AUTOSAR XML (schema 4-2-2)
package /STELLANTIS/EPT/SASWCs
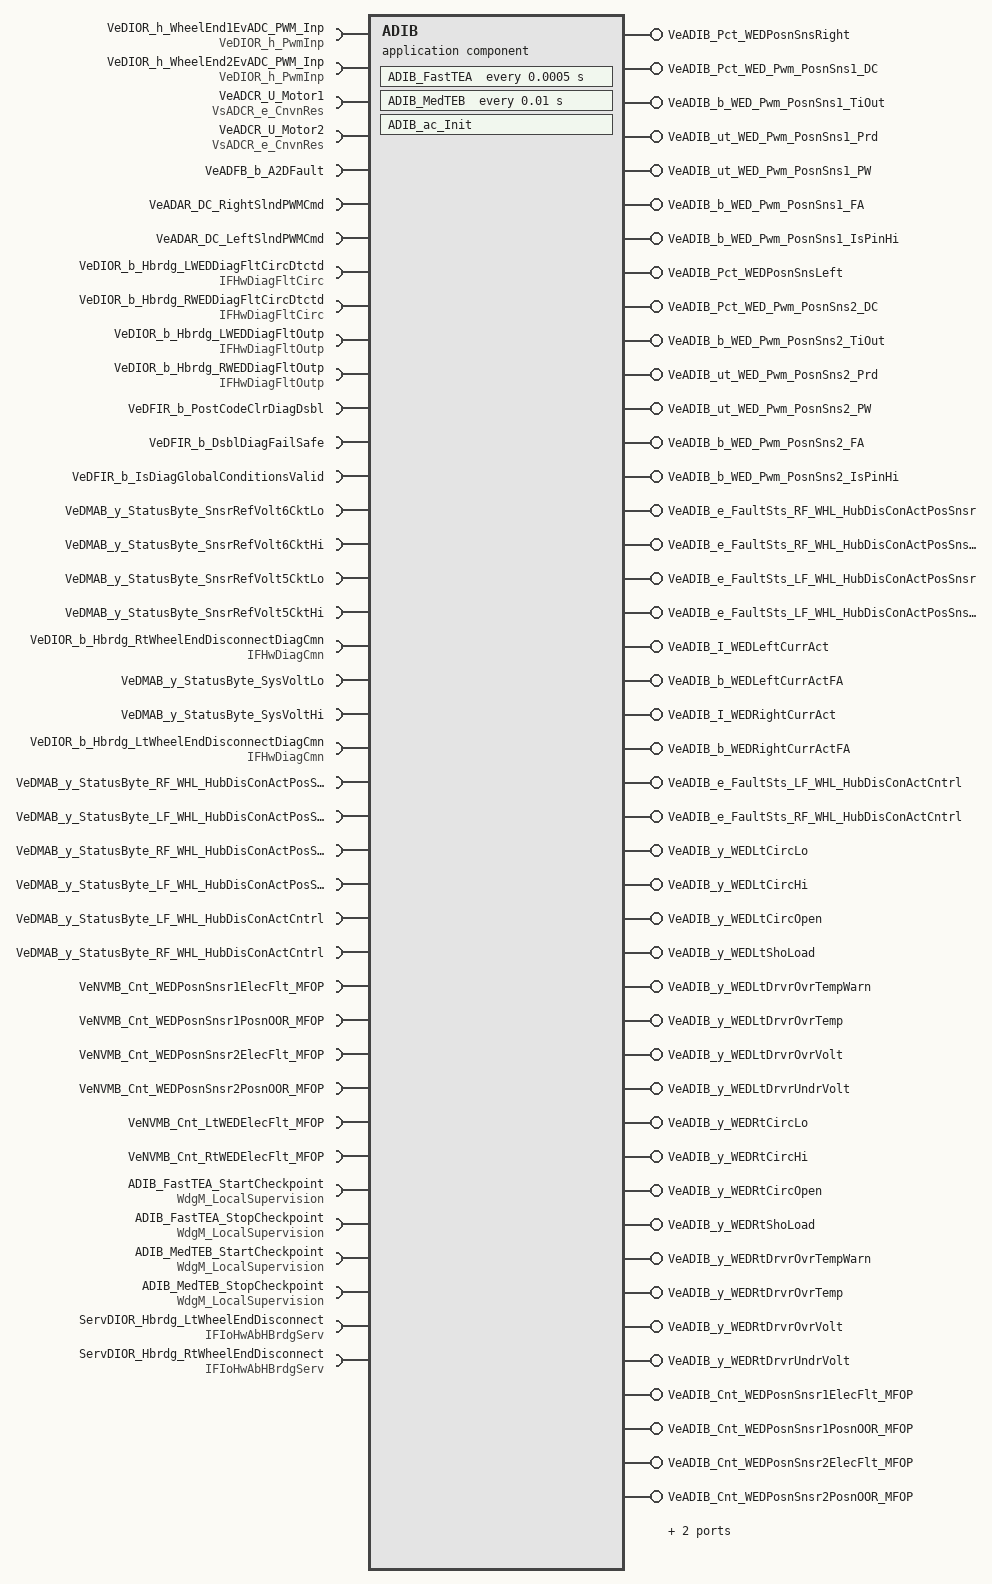
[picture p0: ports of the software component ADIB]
  application sw component type ADIB
    34 x require port:
      VeDIOR_h_WheelEnd1EvADC_PWM_Inp: variation-point={short-label=vpVeDIOR_h_WheelEnd1EvADC_PWM_Inp, sw-syscond=1}, required-interface=VeDIOR_h_PwmInp
        required-com-specs:
          data-element=VeDIOR_Pct_PwmInp_DC, init-value=0
          data-element=VeDIOR_t_PwmInp_PW, init-value=0
          data-element=VeDIOR_t_PwmInp_Prd, init-value=0
          data-element=VeDIOR_b_IsPinHi, init-value=0
          data-element=VeDIOR_b_PwmInp_TiOutSts, init-value=0
          data-element=VeDIOR_b_PwmInp_EnbldSts, init-value=0
      VeDIOR_h_WheelEnd2EvADC_PWM_Inp: variation-point={short-label=vpVeDIOR_h_WheelEnd2EvADC_PWM_Inp, sw-syscond=1}, required-interface=VeDIOR_h_PwmInp
        required-com-specs:
          data-element=VeDIOR_Pct_PwmInp_DC, init-value=0
          data-element=VeDIOR_t_PwmInp_PW, init-value=0
          data-element=VeDIOR_t_PwmInp_Prd, init-value=0
          data-element=VeDIOR_b_IsPinHi, init-value=0
          data-element=VeDIOR_b_PwmInp_TiOutSts, init-value=0
          data-element=VeDIOR_b_PwmInp_EnbldSts, init-value=0
      VeADCR_U_Motor1: variation-point={short-label=vpVeADCR_U_Motor1, sw-syscond=1}, nonqueued-receiver-com-spec{data-element=VsADCR_e_CnvnRes, init-value={short-label=DefaultInitValue_IDTRAdcInpResData, fields=[0, 0]}}, required-interface=VsADCR_e_CnvnRes
      VeADCR_U_Motor2: variation-point={short-label=vpVeADCR_U_Motor2, sw-syscond=1}, nonqueued-receiver-com-spec{data-element=VsADCR_e_CnvnRes, init-value={short-label=DefaultInitValue_IDTRAdcInpResData, fields=[0, 0]}}, required-interface=VsADCR_e_CnvnRes
      VeADFB_b_A2DFault: variation-point={short-label=vpVeADFB_b_A2DFault, sw-syscond=1}, nonqueued-receiver-com-spec{data-element=Value, init-value=0}, required-interface=VeADFB_b_A2DFault
      VeADAR_DC_RightSlndPWMCmd: variation-point={short-label=vpVeADAR_DC_RightSlndPWMCmd, sw-syscond=1}, nonqueued-receiver-com-spec{data-element=Value, init-value=0}, required-interface=VeADAR_DC_RightSlndPWMCmd
      VeADAR_DC_LeftSlndPWMCmd: variation-point={short-label=vpVeADAR_DC_LeftSlndPWMCmd, sw-syscond=1}, nonqueued-receiver-com-spec{data-element=Value, init-value=0}, required-interface=VeADAR_DC_LeftSlndPWMCmd
      VeDIOR_b_Hbrdg_LWEDDiagFltCircDtctd: variation-point={short-label=vpVeDIOR_b_Hbrdg_LWEDDiagFltCircDtctd, sw-syscond=1}, required-interface=IFHwDiagFltCirc
        required-com-specs:
          {data-element=CircShoLo, init-value={short-label=DefaultInitValue_IDTCondPresence, fields=[0, 0, 0, 0, 0, 0, 0, 0]}}
          {data-element=CircShoHi, init-value={short-label=DefaultInitValue_IDTCondPresence, fields=[0, 0, 0, 0, 0, 0, 0, 0]}}
          {data-element=CircOpen, init-value={short-label=DefaultInitValue_IDTCondPresence, fields=[0, 0, 0, 0, 0, 0, 0, 0]}}
          {data-element=ShoLoad, init-value={short-label=DefaultInitValue_IDTCondPresence, fields=[0, 0, 0, 0, 0, 0, 0, 0]}}
      VeDIOR_b_Hbrdg_RWEDDiagFltCircDtctd: variation-point={short-label=vpVeDIOR_b_Hbrdg_RWEDDiagFltCircDtctd, sw-syscond=1}, required-interface=IFHwDiagFltCirc
        required-com-specs:
          {data-element=CircShoLo, init-value={short-label=DefaultInitValue_IDTCondPresence, fields=[0, 0, 0, 0, 0, 0, 0, 0]}}
          {data-element=CircShoHi, init-value={short-label=DefaultInitValue_IDTCondPresence, fields=[0, 0, 0, 0, 0, 0, 0, 0]}}
          {data-element=CircOpen, init-value={short-label=DefaultInitValue_IDTCondPresence, fields=[0, 0, 0, 0, 0, 0, 0, 0]}}
          {data-element=ShoLoad, init-value={short-label=DefaultInitValue_IDTCondPresence, fields=[0, 0, 0, 0, 0, 0, 0, 0]}}
      VeDIOR_b_Hbrdg_LWEDDiagFltOutp: variation-point={short-label=vpVeDIOR_b_Hbrdg_LWEDDiagFltOutp, sw-syscond=1}, required-interface=IFHwDiagFltOutp
        required-com-specs:
          {data-element=DrvrOvrTempWarn, init-value={short-label=DefaultInitValue_IDTCondPresence, fields=[0, 0, 0, 0, 0, 0, 0, 0]}}
          {data-element=DrvrOvrTempDtctd, init-value={short-label=DefaultInitValue_IDTCondPresence, fields=[0, 0, 0, 0, 0, 0, 0, 0]}}
          {data-element=DrvrOvrVoltDtctd, init-value={short-label=DefaultInitValue_IDTCondPresence, fields=[0, 0, 0, 0, 0, 0, 0, 0]}}
          {data-element=DrvrUndrVoltDtctd, init-value={short-label=DefaultInitValue_IDTCondPresence, fields=[0, 0, 0, 0, 0, 0, 0, 0]}}
      VeDIOR_b_Hbrdg_RWEDDiagFltOutp: variation-point={short-label=vpVeDIOR_b_Hbrdg_RWEDDiagFltOutp, sw-syscond=1}, required-interface=IFHwDiagFltOutp
        required-com-specs:
          {data-element=DrvrOvrTempWarn, init-value={short-label=DefaultInitValue_IDTCondPresence, fields=[0, 0, 0, 0, 0, 0, 0, 0]}}
          {data-element=DrvrOvrTempDtctd, init-value={short-label=DefaultInitValue_IDTCondPresence, fields=[0, 0, 0, 0, 0, 0, 0, 0]}}
          {data-element=DrvrOvrVoltDtctd, init-value={short-label=DefaultInitValue_IDTCondPresence, fields=[0, 0, 0, 0, 0, 0, 0, 0]}}
          {data-element=DrvrUndrVoltDtctd, init-value={short-label=DefaultInitValue_IDTCondPresence, fields=[0, 0, 0, 0, 0, 0, 0, 0]}}
      VeDFIR_b_PostCodeClrDiagDsbl: variation-point={short-label=vpVeDFIR_b_PostCodeClrDiagDsbl, sw-syscond=1}, nonqueued-receiver-com-spec{data-element=Value, init-value=0}, required-interface=VeDFIR_b_PostCodeClrDiagDsbl
      VeDFIR_b_DsblDiagFailSafe: variation-point={short-label=vpVeDFIR_b_DsblDiagFailSafe, sw-syscond=1}, nonqueued-receiver-com-spec{data-element=Value, init-value=0}, required-interface=VeDFIR_b_DsblDiagFailSafe
      VeDFIR_b_IsDiagGlobalConditionsValid: variation-point={short-label=vpVeDFIR_b_IsDiagGlobalConditionsValid, sw-syscond=1}, nonqueued-receiver-com-spec{data-element=Value, init-value=0}, required-interface=VeDFIR_b_IsDiagGlobalConditionsValid
      VeDMAB_y_StatusByte_SnsrRefVolt6CktLo: variation-point={short-label=vpVeDMAB_y_StatusByte_SnsrRefVolt6CktLo, sw-syscond=1}, nonqueued-receiver-com-spec{data-element=Value, init-value=0}, required-interface=VeDMAB_y_StatusByte_SnsrRefVolt6CktLo
      VeDMAB_y_StatusByte_SnsrRefVolt6CktHi: variation-point={short-label=vpVeDMAB_y_StatusByte_SnsrRefVolt6CktHi, sw-syscond=1}, nonqueued-receiver-com-spec{data-element=Value, init-value=0}, required-interface=VeDMAB_y_StatusByte_SnsrRefVolt6CktHi
      VeDMAB_y_StatusByte_SnsrRefVolt5CktLo: variation-point={short-label=vpVeDMAB_y_StatusByte_SnsrRefVolt5CktLo, sw-syscond=1}, nonqueued-receiver-com-spec{data-element=Value, init-value=0}, required-interface=VeDMAB_y_StatusByte_SnsrRefVolt5CktLo
      VeDMAB_y_StatusByte_SnsrRefVolt5CktHi: variation-point={short-label=vpVeDMAB_y_StatusByte_SnsrRefVolt5CktHi, sw-syscond=1}, nonqueued-receiver-com-spec{data-element=Value, init-value=0}, required-interface=VeDMAB_y_StatusByte_SnsrRefVolt5CktHi
      VeDIOR_b_Hbrdg_RtWheelEndDisconnectDiagCmn: variation-point={short-label=vpVeDIOR_b_Hbrdg_RtWheelEndDisconnectDiagCmn, sw-syscond=1}, nonqueued-receiver-com-spec{data-element=b_FailrPrsnt, init-value=0}, required-interface=IFHwDiagCmn
      VeDMAB_y_StatusByte_SysVoltLo: variation-point={short-label=vpVeDMAB_y_StatusByte_SysVoltLo, sw-syscond=1}, nonqueued-receiver-com-spec{data-element=Value, init-value=0}, required-interface=VeDMAB_y_StatusByte_SysVoltLo
      VeDMAB_y_StatusByte_SysVoltHi: variation-point={short-label=vpVeDMAB_y_StatusByte_SysVoltHi, sw-syscond=1}, nonqueued-receiver-com-spec{data-element=Value, init-value=0}, required-interface=VeDMAB_y_StatusByte_SysVoltHi
      VeDIOR_b_Hbrdg_LtWheelEndDisconnectDiagCmn: variation-point={short-label=vpVeDIOR_b_Hbrdg_LtWheelEndDisconnectDiagCmn, sw-syscond=1}, nonqueued-receiver-com-spec{data-element=b_FailrPrsnt, init-value=0}, required-interface=IFHwDiagCmn
      VeDMAB_y_StatusByte_RF_WHL_HubDisConActPosSnsr: variation-point={short-label=vpVeDMAB_y_StatusByte_RF_WHL_HubDisConActPosSnsr, sw-syscond=1}, nonqueued-receiver-com-spec{data-element=Value, init-value=0}, required-interface=VeDMAB_y_StatusByte_RF_WHL_HubDisConActPosSnsr
      VeDMAB_y_StatusByte_LF_WHL_HubDisConActPosSnsrCktPerf: variation-point={short-label=vpVeDMAB_y_StatusByte_LF_WHL_HubDisConActPosSnsrCktPerf, sw-syscond=1}, nonqueued-receiver-com-spec{data-element=Value, init-value=0}, required-interface=VeDMAB_y_StatusByte_LF_WHL_HubDisConActPosSnsrCktPerf
      VeDMAB_y_StatusByte_RF_WHL_HubDisConActPosSnsrCktPerf: variation-point={short-label=vpVeDMAB_y_StatusByte_RF_WHL_HubDisConActPosSnsrCktPerf, sw-syscond=1}, nonqueued-receiver-com-spec{data-element=Value, init-value=0}, required-interface=VeDMAB_y_StatusByte_RF_WHL_HubDisConActPosSnsrCktPerf
      VeDMAB_y_StatusByte_LF_WHL_HubDisConActPosSnsr: variation-point={short-label=vpVeDMAB_y_StatusByte_LF_WHL_HubDisConActPosSnsr, sw-syscond=1}, nonqueued-receiver-com-spec{data-element=Value, init-value=0}, required-interface=VeDMAB_y_StatusByte_LF_WHL_HubDisConActPosSnsr
      VeDMAB_y_StatusByte_LF_WHL_HubDisConActCntrl: variation-point={short-label=vpVeDMAB_y_StatusByte_LF_WHL_HubDisConActCntrl, sw-syscond=1}, nonqueued-receiver-com-spec{data-element=Value, init-value=0}, required-interface=VeDMAB_y_StatusByte_LF_WHL_HubDisConActCntrl
      VeDMAB_y_StatusByte_RF_WHL_HubDisConActCntrl: variation-point={short-label=vpVeDMAB_y_StatusByte_RF_WHL_HubDisConActCntrl, sw-syscond=1}, nonqueued-receiver-com-spec{data-element=Value, init-value=0}, required-interface=VeDMAB_y_StatusByte_RF_WHL_HubDisConActCntrl
      VeNVMB_Cnt_WEDPosnSnsr1ElecFlt_MFOP: variation-point={short-label=vpVeNVMB_Cnt_WEDPosnSnsr1ElecFlt_MFOP, sw-syscond=1}, nonqueued-receiver-com-spec{data-element=Value, init-value=0}, required-interface=VeNVMB_Cnt_WEDPosnSnsr1ElecFlt_MFOP
      VeNVMB_Cnt_WEDPosnSnsr1PosnOOR_MFOP: variation-point={short-label=vpVeNVMB_Cnt_WEDPosnSnsr1PosnOOR_MFOP, sw-syscond=1}, nonqueued-receiver-com-spec{data-element=Value, init-value=0}, required-interface=VeNVMB_Cnt_WEDPosnSnsr1PosnOOR_MFOP
      VeNVMB_Cnt_WEDPosnSnsr2ElecFlt_MFOP: variation-point={short-label=vpVeNVMB_Cnt_WEDPosnSnsr2ElecFlt_MFOP, sw-syscond=1}, nonqueued-receiver-com-spec{data-element=Value, init-value=0}, required-interface=VeNVMB_Cnt_WEDPosnSnsr2ElecFlt_MFOP
      VeNVMB_Cnt_WEDPosnSnsr2PosnOOR_MFOP: variation-point={short-label=vpVeNVMB_Cnt_WEDPosnSnsr2PosnOOR_MFOP, sw-syscond=1}, nonqueued-receiver-com-spec{data-element=Value, init-value=0}, required-interface=VeNVMB_Cnt_WEDPosnSnsr2PosnOOR_MFOP
      VeNVMB_Cnt_LtWEDElecFlt_MFOP: variation-point={short-label=vpVeNVMB_Cnt_LtWEDElecFlt_MFOP, sw-syscond=1}, nonqueued-receiver-com-spec{data-element=Value, init-value=0}, required-interface=VeNVMB_Cnt_LtWEDElecFlt_MFOP
      VeNVMB_Cnt_RtWEDElecFlt_MFOP: variation-point={short-label=vpVeNVMB_Cnt_RtWEDElecFlt_MFOP, sw-syscond=1}, nonqueued-receiver-com-spec{data-element=Value, init-value=0}, required-interface=VeNVMB_Cnt_RtWEDElecFlt_MFOP
    46 x provide port:
      VeADIB_Pct_WEDPosnSnsRight: variation-point={short-label=vpVeADIB_Pct_WEDPosnSnsRight, sw-syscond=1}, nonqueued-sender-com-spec{data-element=Value, init-value=0}, provided-interface=VeADIB_Pct_WEDPosnSnsRight
      VeADIB_Pct_WED_Pwm_PosnSns1_DC: variation-point={short-label=vpVeADIB_Pct_WED_Pwm_PosnSns1_DC, sw-syscond=1}, nonqueued-sender-com-spec{data-element=Value, init-value=0}, provided-interface=VeADIB_Pct_WED_Pwm_PosnSns1_DC
      VeADIB_b_WED_Pwm_PosnSns1_TiOut: variation-point={short-label=vpVeADIB_b_WED_Pwm_PosnSns1_TiOut, sw-syscond=1}, nonqueued-sender-com-spec{data-element=Value, init-value=0}, provided-interface=VeADIB_b_WED_Pwm_PosnSns1_TiOut
      VeADIB_ut_WED_Pwm_PosnSns1_Prd: variation-point={short-label=vpVeADIB_ut_WED_Pwm_PosnSns1_Prd, sw-syscond=1}, nonqueued-sender-com-spec{data-element=Value, init-value=0}, provided-interface=VeADIB_ut_WED_Pwm_PosnSns1_Prd
      VeADIB_ut_WED_Pwm_PosnSns1_PW: variation-point={short-label=vpVeADIB_ut_WED_Pwm_PosnSns1_PW, sw-syscond=1}, nonqueued-sender-com-spec{data-element=Value, init-value=0}, provided-interface=VeADIB_ut_WED_Pwm_PosnSns1_PW
      VeADIB_b_WED_Pwm_PosnSns1_FA: variation-point={short-label=vpVeADIB_b_WED_Pwm_PosnSns1_FA, sw-syscond=1}, nonqueued-sender-com-spec{data-element=Value, init-value=0}, provided-interface=VeADIB_b_WED_Pwm_PosnSns1_FA
      VeADIB_b_WED_Pwm_PosnSns1_IsPinHi: variation-point={short-label=vpVeADIB_b_WED_Pwm_PosnSns1_IsPinHi, sw-syscond=1}, nonqueued-sender-com-spec{data-element=Value, init-value=0}, provided-interface=VeADIB_b_WED_Pwm_PosnSns1_IsPinHi
      VeADIB_Pct_WEDPosnSnsLeft: variation-point={short-label=vpVeADIB_Pct_WEDPosnSnsLeft, sw-syscond=1}, nonqueued-sender-com-spec{data-element=Value, init-value=0}, provided-interface=VeADIB_Pct_WEDPosnSnsLeft
      VeADIB_Pct_WED_Pwm_PosnSns2_DC: variation-point={short-label=vpVeADIB_Pct_WED_Pwm_PosnSns2_DC, sw-syscond=1}, nonqueued-sender-com-spec{data-element=Value, init-value=0}, provided-interface=VeADIB_Pct_WED_Pwm_PosnSns2_DC
      VeADIB_b_WED_Pwm_PosnSns2_TiOut: variation-point={short-label=vpVeADIB_b_WED_Pwm_PosnSns2_TiOut, sw-syscond=1}, nonqueued-sender-com-spec{data-element=Value, init-value=0}, provided-interface=VeADIB_b_WED_Pwm_PosnSns2_TiOut
      VeADIB_ut_WED_Pwm_PosnSns2_Prd: variation-point={short-label=vpVeADIB_ut_WED_Pwm_PosnSns2_Prd, sw-syscond=1}, nonqueued-sender-com-spec{data-element=Value, init-value=0}, provided-interface=VeADIB_ut_WED_Pwm_PosnSns2_Prd
      VeADIB_ut_WED_Pwm_PosnSns2_PW: variation-point={short-label=vpVeADIB_ut_WED_Pwm_PosnSns2_PW, sw-syscond=1}, nonqueued-sender-com-spec{data-element=Value, init-value=0}, provided-interface=VeADIB_ut_WED_Pwm_PosnSns2_PW
      VeADIB_b_WED_Pwm_PosnSns2_FA: variation-point={short-label=vpVeADIB_b_WED_Pwm_PosnSns2_FA, sw-syscond=1}, nonqueued-sender-com-spec{data-element=Value, init-value=0}, provided-interface=VeADIB_b_WED_Pwm_PosnSns2_FA
      VeADIB_b_WED_Pwm_PosnSns2_IsPinHi: variation-point={short-label=vpVeADIB_b_WED_Pwm_PosnSns2_IsPinHi, sw-syscond=1}, nonqueued-sender-com-spec{data-element=Value, init-value=0}, provided-interface=VeADIB_b_WED_Pwm_PosnSns2_IsPinHi
      VeADIB_e_FaultSts_RF_WHL_HubDisConActPosSnsr: variation-point={short-label=vpVeADIB_e_FaultSts_RF_WHL_HubDisConActPosSnsr, sw-syscond=1}, nonqueued-sender-com-spec{data-element=Value, init-value=CeDFIB_e_Init}, provided-interface=VeADIB_e_FaultSts_RF_WHL_HubDisConActPosSnsr
      VeADIB_e_FaultSts_RF_WHL_HubDisConActPosSnsrCktPerf: variation-point={short-label=vpVeADIB_e_FaultSts_RF_WHL_HubDisConActPosSnsrCktPerf, sw-syscond=1}, nonqueued-sender-com-spec{data-element=Value, init-value=CeDFIB_e_Init}, provided-interface=VeADIB_e_FaultSts_RF_WHL_HubDisConActPosSnsrCktPerf
      VeADIB_e_FaultSts_LF_WHL_HubDisConActPosSnsr: variation-point={short-label=vpVeADIB_e_FaultSts_LF_WHL_HubDisConActPosSnsr, sw-syscond=1}, nonqueued-sender-com-spec{data-element=Value, init-value=CeDFIB_e_Init}, provided-interface=VeADIB_e_FaultSts_LF_WHL_HubDisConActPosSnsr
      VeADIB_e_FaultSts_LF_WHL_HubDisConActPosSnsrCktPerf: variation-point={short-label=vpVeADIB_e_FaultSts_LF_WHL_HubDisConActPosSnsrCktPerf, sw-syscond=1}, nonqueued-sender-com-spec{data-element=Value, init-value=CeDFIB_e_Init}, provided-interface=VeADIB_e_FaultSts_LF_WHL_HubDisConActPosSnsrCktPerf
      VeADIB_I_WEDLeftCurrAct: variation-point={short-label=vpVeADIB_I_WEDLeftCurrAct, sw-syscond=1}, nonqueued-sender-com-spec{data-element=Value, init-value=0}, provided-interface=VeADIB_I_WEDLeftCurrAct
      VeADIB_b_WEDLeftCurrActFA: variation-point={short-label=vpVeADIB_b_WEDLeftCurrActFA, sw-syscond=1}, nonqueued-sender-com-spec{data-element=Value, init-value=0}, provided-interface=VeADIB_b_WEDLeftCurrActFA
      VeADIB_I_WEDRightCurrAct: variation-point={short-label=vpVeADIB_I_WEDRightCurrAct, sw-syscond=1}, nonqueued-sender-com-spec{data-element=Value, init-value=0}, provided-interface=VeADIB_I_WEDRightCurrAct
      VeADIB_b_WEDRightCurrActFA: variation-point={short-label=vpVeADIB_b_WEDRightCurrActFA, sw-syscond=1}, nonqueued-sender-com-spec{data-element=Value, init-value=0}, provided-interface=VeADIB_b_WEDRightCurrActFA
      VeADIB_e_FaultSts_LF_WHL_HubDisConActCntrl: variation-point={short-label=vpVeADIB_e_FaultSts_LF_WHL_HubDisConActCntrl, sw-syscond=1}, nonqueued-sender-com-spec{data-element=Value, init-value=CeDFIB_e_Init}, provided-interface=VeADIB_e_FaultSts_LF_WHL_HubDisConActCntrl
      VeADIB_e_FaultSts_RF_WHL_HubDisConActCntrl: variation-point={short-label=vpVeADIB_e_FaultSts_RF_WHL_HubDisConActCntrl, sw-syscond=1}, nonqueued-sender-com-spec{data-element=Value, init-value=CeDFIB_e_Init}, provided-interface=VeADIB_e_FaultSts_RF_WHL_HubDisConActCntrl
      VeADIB_y_WEDLtCircLo: variation-point={short-label=vpVeADIB_y_WEDLtCircLo, sw-syscond=1}, nonqueued-sender-com-spec{data-element=Value, init-value=0}, provided-interface=VeADIB_y_WEDLtCircLo
      VeADIB_y_WEDLtCircHi: variation-point={short-label=vpVeADIB_y_WEDLtCircHi, sw-syscond=1}, nonqueued-sender-com-spec{data-element=Value, init-value=0}, provided-interface=VeADIB_y_WEDLtCircHi
      VeADIB_y_WEDLtCircOpen: variation-point={short-label=vpVeADIB_y_WEDLtCircOpen, sw-syscond=1}, nonqueued-sender-com-spec{data-element=Value, init-value=0}, provided-interface=VeADIB_y_WEDLtCircOpen
      VeADIB_y_WEDLtShoLoad: variation-point={short-label=vpVeADIB_y_WEDLtShoLoad, sw-syscond=1}, nonqueued-sender-com-spec{data-element=Value, init-value=0}, provided-interface=VeADIB_y_WEDLtShoLoad
      VeADIB_y_WEDLtDrvrOvrTempWarn: variation-point={short-label=vpVeADIB_y_WEDLtDrvrOvrTempWarn, sw-syscond=1}, nonqueued-sender-com-spec{data-element=Value, init-value=0}, provided-interface=VeADIB_y_WEDLtDrvrOvrTempWarn
      VeADIB_y_WEDLtDrvrOvrTemp: variation-point={short-label=vpVeADIB_y_WEDLtDrvrOvrTemp, sw-syscond=1}, nonqueued-sender-com-spec{data-element=Value, init-value=0}, provided-interface=VeADIB_y_WEDLtDrvrOvrTemp
      VeADIB_y_WEDLtDrvrOvrVolt: variation-point={short-label=vpVeADIB_y_WEDLtDrvrOvrVolt, sw-syscond=1}, nonqueued-sender-com-spec{data-element=Value, init-value=0}, provided-interface=VeADIB_y_WEDLtDrvrOvrVolt
      VeADIB_y_WEDLtDrvrUndrVolt: variation-point={short-label=vpVeADIB_y_WEDLtDrvrUndrVolt, sw-syscond=1}, nonqueued-sender-com-spec{data-element=Value, init-value=0}, provided-interface=VeADIB_y_WEDLtDrvrUndrVolt
      VeADIB_y_WEDRtCircLo: variation-point={short-label=vpVeADIB_y_WEDRtCircLo, sw-syscond=1}, nonqueued-sender-com-spec{data-element=Value, init-value=0}, provided-interface=VeADIB_y_WEDRtCircLo
      VeADIB_y_WEDRtCircHi: variation-point={short-label=vpVeADIB_y_WEDRtCircHi, sw-syscond=1}, nonqueued-sender-com-spec{data-element=Value, init-value=0}, provided-interface=VeADIB_y_WEDRtCircHi
      VeADIB_y_WEDRtCircOpen: variation-point={short-label=vpVeADIB_y_WEDRtCircOpen, sw-syscond=1}, nonqueued-sender-com-spec{data-element=Value, init-value=0}, provided-interface=VeADIB_y_WEDRtCircOpen
      VeADIB_y_WEDRtShoLoad: variation-point={short-label=vpVeADIB_y_WEDRtShoLoad, sw-syscond=1}, nonqueued-sender-com-spec{data-element=Value, init-value=0}, provided-interface=VeADIB_y_WEDRtShoLoad
      VeADIB_y_WEDRtDrvrOvrTempWarn: variation-point={short-label=vpVeADIB_y_WEDRtDrvrOvrTempWarn, sw-syscond=1}, nonqueued-sender-com-spec{data-element=Value, init-value=0}, provided-interface=VeADIB_y_WEDRtDrvrOvrTempWarn
      VeADIB_y_WEDRtDrvrOvrTemp: variation-point={short-label=vpVeADIB_y_WEDRtDrvrOvrTemp, sw-syscond=1}, nonqueued-sender-com-spec{data-element=Value, init-value=0}, provided-interface=VeADIB_y_WEDRtDrvrOvrTemp
      VeADIB_y_WEDRtDrvrOvrVolt: variation-point={short-label=vpVeADIB_y_WEDRtDrvrOvrVolt, sw-syscond=1}, nonqueued-sender-com-spec{data-element=Value, init-value=0}, provided-interface=VeADIB_y_WEDRtDrvrOvrVolt
      VeADIB_y_WEDRtDrvrUndrVolt: variation-point={short-label=vpVeADIB_y_WEDRtDrvrUndrVolt, sw-syscond=1}, nonqueued-sender-com-spec{data-element=Value, init-value=0}, provided-interface=VeADIB_y_WEDRtDrvrUndrVolt
      VeADIB_Cnt_WEDPosnSnsr1ElecFlt_MFOP: variation-point={short-label=vpVeADIB_Cnt_WEDPosnSnsr1ElecFlt_MFOP, sw-syscond=1}, nonqueued-sender-com-spec{data-element=Value, init-value=0}, provided-interface=VeADIB_Cnt_WEDPosnSnsr1ElecFlt_MFOP
      VeADIB_Cnt_WEDPosnSnsr1PosnOOR_MFOP: variation-point={short-label=vpVeADIB_Cnt_WEDPosnSnsr1PosnOOR_MFOP, sw-syscond=1}, nonqueued-sender-com-spec{data-element=Value, init-value=0}, provided-interface=VeADIB_Cnt_WEDPosnSnsr1PosnOOR_MFOP
      VeADIB_Cnt_WEDPosnSnsr2ElecFlt_MFOP: variation-point={short-label=vpVeADIB_Cnt_WEDPosnSnsr2ElecFlt_MFOP, sw-syscond=1}, nonqueued-sender-com-spec{data-element=Value, init-value=0}, provided-interface=VeADIB_Cnt_WEDPosnSnsr2ElecFlt_MFOP
      VeADIB_Cnt_WEDPosnSnsr2PosnOOR_MFOP: variation-point={short-label=vpVeADIB_Cnt_WEDPosnSnsr2PosnOOR_MFOP, sw-syscond=1}, nonqueued-sender-com-spec{data-element=Value, init-value=0}, provided-interface=VeADIB_Cnt_WEDPosnSnsr2PosnOOR_MFOP
      VeADIB_Cnt_LtWEDElecFlt_MFOP: variation-point={short-label=vpVeADIB_Cnt_LtWEDElecFlt_MFOP, sw-syscond=1}, nonqueued-sender-com-spec{data-element=Value, init-value=0}, provided-interface=VeADIB_Cnt_LtWEDElecFlt_MFOP
      VeADIB_Cnt_RtWEDElecFlt_MFOP: variation-point={short-label=vpVeADIB_Cnt_RtWEDElecFlt_MFOP, sw-syscond=1}, nonqueued-sender-com-spec{data-element=Value, init-value=0}, provided-interface=VeADIB_Cnt_RtWEDElecFlt_MFOP
    6 x require port:
      ADIB_FastTEA_StartCheckpoint: variation-point={short-label=vpADIB_FastTEA_StartCheckpoint, sw-syscond=1}, client-com-spec=CheckpointReached, required-interface=WdgM_LocalSupervision
      ADIB_FastTEA_StopCheckpoint: variation-point={short-label=vpADIB_FastTEA_StopCheckpoint, sw-syscond=1}, client-com-spec=CheckpointReached, required-interface=WdgM_LocalSupervision
      ADIB_MedTEB_StartCheckpoint: client-com-spec=CheckpointReached, required-interface=WdgM_LocalSupervision
      ADIB_MedTEB_StopCheckpoint: client-com-spec=CheckpointReached, required-interface=WdgM_LocalSupervision
      ServDIOR_Hbrdg_LtWheelEndDisconnect: variation-point={short-label=vpServDIOR_Hbrdg_LtWheelEndDisconnect, sw-syscond=1}, client-com-spec=SetDIOR_CurrLim, required-interface=IFIoHwAbHBrdgServ
      ServDIOR_Hbrdg_RtWheelEndDisconnect: variation-point={short-label=vpServDIOR_Hbrdg_RtWheelEndDisconnect, sw-syscond=1}, client-com-spec=SetDIOR_CurrLim, required-interface=IFIoHwAbHBrdgServ
    behavior IB_ADIB: data-type-mapping=[msADTtoIDTMapping, ADTtoIDTMapping], handle-termination-and-restart=NO-SUPPORT
      timing event Event_FastTEA: start-on-event=ADIB_FastTEA, period=0.0005
      timing event Event_MedTEB: start-on-event=ADIB_MedTEB, period=0.01
      init event Event_ADIB_ac_Init: start-on-event=ADIB_ac_Init
      explicit-inter-runnable-variables:
        14 x data, all with category=VALUE, sw-calibration-access=READ-ONLY, init-value=0:
          VeADIB_b_LtWED_FA_IRV: type=Boolean, variation-point={short-label=vpVeADIB_b_LtWED_FA_IRV, sw-syscond=1}
          VeADIB_b_RtWED_FA_IRV: type=Boolean, variation-point={short-label=vpVeADIB_b_RtWED_FA_IRV, sw-syscond=1}
          VeADIB_b_WED_Pwm_PosnSns1_FA1_IRV: type=Boolean, variation-point={short-label=vpVeADIB_b_WED_Pwm_PosnSns1_FA1_IRV, sw-syscond=1}
          VeADIB_b_WED_Pwm_PosnSns1_FaultCriteria_IRV: type=Boolean, variation-point={short-label=vpVeADIB_b_WED_Pwm_PosnSns1_FaultCriteria_IRV, sw-syscond=1}
          VeADIB_b_WED_Pwm_PosnSns2_FA1_IRV: type=Boolean, variation-point={short-label=vpVeADIB_b_WED_Pwm_PosnSns2_FA1_IRV, sw-syscond=1}
          VeADIB_b_WED_Pwm_PosnSns2_FualtCriteria_IRV: type=Boolean, variation-point={short-label=vpVeADIB_b_WED_Pwm_PosnSns2_FualtCriteria_IRV, sw-syscond=1}
          VeADIB_b_WED_Pwm_PosnSns1_TiOut1_IRV: type=Boolean, variation-point={short-label=vpVeADIB_b_WED_Pwm_PosnSns1_TiOut1_IRV, sw-syscond=1}
          VeADIB_b_WED_Pwm_PosnSns1_IsPinHi1_IRV: type=Boolean, variation-point={short-label=vpVeADIB_b_WED_Pwm_PosnSns1_IsPinHi1_IRV, sw-syscond=1}
          VeADIB_ut_WED_Pwm_PosnSns1_Prd1_IRV: type=Float, variation-point={short-label=vpVeADIB_ut_WED_Pwm_PosnSns1_Prd1_IRV, sw-syscond=1}
          VeADIB_Pct_WED_Pwm_PosnSns1_DCReal_IRV: type=Float, variation-point={short-label=vpVeADIB_Pct_WED_Pwm_PosnSns1_DCReal_IRV, sw-syscond=1}
          VeADIB_b_WED_Pwm_PosnSns2_TiOut1_IRV: type=Boolean, variation-point={short-label=vpVeADIB_b_WED_Pwm_PosnSns2_TiOut1_IRV, sw-syscond=1}
          VeADIB_b_WED_Pwm_PosnSns2_IsPinHi1_IRV: type=Boolean, variation-point={short-label=vpVeADIB_b_WED_Pwm_PosnSns2_IsPinHi1_IRV, sw-syscond=1}
          VeADIB_ut_WED_Pwm_PosnSns2_Prd1_IRV: type=Float, variation-point={short-label=vpVeADIB_ut_WED_Pwm_PosnSns2_Prd1_IRV, sw-syscond=1}
          VeADIB_Pct_WED_Pwm_PosnSns2_DCReal_IRV: type=Float, variation-point={short-label=vpVeADIB_Pct_WED_Pwm_PosnSns2_DCReal_IRV, sw-syscond=1}
      runnable ADIB_ac_Init
        data-send-points:
          16 x access:
            OUT_VeADIB_Pct_WED_Pwm_PosnSns1_DC_Value: accessed-variable=VeADIB_Pct_WED_Pwm_PosnSns1_DC.Value, variation-point={short-label=vpOUT_VeADIB_Pct_WED_Pwm_PosnSns1_DC_Value, sw-syscond=1}
            OUT_VeADIB_Pct_WEDPosnSnsRight_Value: accessed-variable=VeADIB_Pct_WEDPosnSnsRight.Value, variation-point={short-label=vpOUT_VeADIB_Pct_WEDPosnSnsRight_Value, sw-syscond=1}
            OUT_VeADIB_ut_WED_Pwm_PosnSns1_Prd_Value: accessed-variable=VeADIB_ut_WED_Pwm_PosnSns1_Prd.Value, variation-point={short-label=vpOUT_VeADIB_ut_WED_Pwm_PosnSns1_Prd_Value, sw-syscond=1}
            OUT_VeADIB_ut_WED_Pwm_PosnSns1_PW_Value: accessed-variable=VeADIB_ut_WED_Pwm_PosnSns1_PW.Value, variation-point={short-label=vpOUT_VeADIB_ut_WED_Pwm_PosnSns1_PW_Value, sw-syscond=1}
            OUT_VeADIB_b_WED_Pwm_PosnSns1_IsPinHi_Value: accessed-variable=VeADIB_b_WED_Pwm_PosnSns1_IsPinHi.Value, variation-point={short-label=vpOUT_VeADIB_b_WED_Pwm_PosnSns1_IsPinHi_Value, sw-syscond=1}
            OUT_VeADIB_e_FaultSts_RF_WHL_HubDisConActPosSnsr_Value: accessed-variable=VeADIB_e_FaultSts_RF_WHL_HubDisConActPosSnsr.Value, variation-point={short-label=vpOUT_VeADIB_e_FaultSts_RF_WHL_HubDisConActPosSnsr_Value, sw-syscond=1}
            OUT_VeADIB_e_FaultSts_RF_WHL_HubDisConActPosSnsrCktPerf_Value: accessed-variable=VeADIB_e_FaultSts_RF_WHL_HubDisConActPosSnsrCktPerf.Value, variation-point={short-label=vpOUT_VeADIB_e_FaultSts_RF_WHL_HubDisConActPosSnsrCktPerf_Value, sw-syscond=1}
            OUT_VeADIB_Pct_WED_Pwm_PosnSns2_DC_Value: accessed-variable=VeADIB_Pct_WED_Pwm_PosnSns2_DC.Value, variation-point={short-label=vpOUT_VeADIB_Pct_WED_Pwm_PosnSns2_DC_Value, sw-syscond=1}
            OUT_VeADIB_Pct_WEDPosnSnsLeft_Value: accessed-variable=VeADIB_Pct_WEDPosnSnsLeft.Value, variation-point={short-label=vpOUT_VeADIB_Pct_WEDPosnSnsLeft_Value, sw-syscond=1}
            OUT_VeADIB_ut_WED_Pwm_PosnSns2_Prd_Value: accessed-variable=VeADIB_ut_WED_Pwm_PosnSns2_Prd.Value, variation-point={short-label=vpOUT_VeADIB_ut_WED_Pwm_PosnSns2_Prd_Value, sw-syscond=1}
            OUT_VeADIB_ut_WED_Pwm_PosnSns2_PW_Value: accessed-variable=VeADIB_ut_WED_Pwm_PosnSns2_PW.Value, variation-point={short-label=vpOUT_VeADIB_ut_WED_Pwm_PosnSns2_PW_Value, sw-syscond=1}
            OUT_VeADIB_b_WED_Pwm_PosnSns2_IsPinHi_Value: accessed-variable=VeADIB_b_WED_Pwm_PosnSns2_IsPinHi.Value, variation-point={short-label=vpOUT_VeADIB_b_WED_Pwm_PosnSns2_IsPinHi_Value, sw-syscond=1}
            OUT_VeADIB_e_FaultSts_LF_WHL_HubDisConActPosSnsr_Value: accessed-variable=VeADIB_e_FaultSts_LF_WHL_HubDisConActPosSnsr.Value, variation-point={short-label=vpOUT_VeADIB_e_FaultSts_LF_WHL_HubDisConActPosSnsr_Value, sw-syscond=1}
            OUT_VeADIB_e_FaultSts_LF_WHL_HubDisConActPosSnsrCktPerf_Value: accessed-variable=VeADIB_e_FaultSts_LF_WHL_HubDisConActPosSnsrCktPerf.Value, variation-point={short-label=vpOUT_VeADIB_e_FaultSts_LF_WHL_HubDisConActPosSnsrCktPerf_Value, sw-syscond=1}
            OUT_VeADIB_e_FaultSts_LF_WHL_HubDisConActCntrl_Value: accessed-variable=VeADIB_e_FaultSts_LF_WHL_HubDisConActCntrl.Value, variation-point={short-label=vpOUT_VeADIB_e_FaultSts_LF_WHL_HubDisConActCntrl_Value, sw-syscond=1}
            OUT_VeADIB_e_FaultSts_RF_WHL_HubDisConActCntrl_Value: accessed-variable=VeADIB_e_FaultSts_RF_WHL_HubDisConActCntrl.Value, variation-point={short-label=vpOUT_VeADIB_e_FaultSts_RF_WHL_HubDisConActCntrl_Value, sw-syscond=1}
        8 x sync call, all with timeout=1E-06:
          SC_ServDIOR_Hbrdg_LtWheelEndDisconnect_SetDIOR_CurrLim: operation=ServDIOR_Hbrdg_LtWheelEndDisconnect.SetDIOR_CurrLim, variation-point={short-label=vpSC_ServDIOR_Hbrdg_LtWheelEndDisconnect_SetDIOR_CurrLim, sw-syscond=1}
          SC_ServDIOR_Hbrdg_LtWheelEndDisconnect_SetDIOR_DutyCyc: operation=ServDIOR_Hbrdg_LtWheelEndDisconnect.SetDIOR_DutyCyc, variation-point={short-label=vpSC_ServDIOR_Hbrdg_LtWheelEndDisconnect_SetDIOR_DutyCyc, sw-syscond=1}
          SC_ServDIOR_Hbrdg_LtWheelEndDisconnect_SetDIOR_EnblSt: operation=ServDIOR_Hbrdg_LtWheelEndDisconnect.SetDIOR_EnblSt, variation-point={short-label=vpSC_ServDIOR_Hbrdg_LtWheelEndDisconnect_SetDIOR_EnblSt, sw-syscond=1}
          SC_ServDIOR_Hbrdg_LtWheelEndDisconnect_SetDIOR_Prd: operation=ServDIOR_Hbrdg_LtWheelEndDisconnect.SetDIOR_Prd, variation-point={short-label=vpSC_ServDIOR_Hbrdg_LtWheelEndDisconnect_SetDIOR_Prd, sw-syscond=1}
          SC_ServDIOR_Hbrdg_RtWheelEndDisconnect_SetDIOR_CurrLim: operation=ServDIOR_Hbrdg_RtWheelEndDisconnect.SetDIOR_CurrLim, variation-point={short-label=vpSC_ServDIOR_Hbrdg_RtWheelEndDisconnect_SetDIOR_CurrLim, sw-syscond=1}
          SC_ServDIOR_Hbrdg_RtWheelEndDisconnect_SetDIOR_DutyCyc: operation=ServDIOR_Hbrdg_RtWheelEndDisconnect.SetDIOR_DutyCyc, variation-point={short-label=vpSC_ServDIOR_Hbrdg_RtWheelEndDisconnect_SetDIOR_DutyCyc, sw-syscond=1}
          SC_ServDIOR_Hbrdg_RtWheelEndDisconnect_SetDIOR_EnblSt: operation=ServDIOR_Hbrdg_RtWheelEndDisconnect.SetDIOR_EnblSt, variation-point={short-label=vpSC_ServDIOR_Hbrdg_RtWheelEndDisconnect_SetDIOR_EnblSt, sw-syscond=1}
          SC_ServDIOR_Hbrdg_RtWheelEndDisconnect_SetDIOR_Prd: operation=ServDIOR_Hbrdg_RtWheelEndDisconnect.SetDIOR_Prd, variation-point={short-label=vpSC_ServDIOR_Hbrdg_RtWheelEndDisconnect_SetDIOR_Prd, sw-syscond=1}
        written-local-variables:
          14 x access:
            WV_VeADIB_Pct_WED_Pwm_PosnSns1_DCReal_IRV: accessed-variable=VeADIB_Pct_WED_Pwm_PosnSns1_DCReal_IRV, variation-point={short-label=vpWV_VeADIB_Pct_WED_Pwm_PosnSns1_DCReal_IRV, sw-syscond=1}
            WV_VeADIB_Pct_WED_Pwm_PosnSns2_DCReal_IRV: accessed-variable=VeADIB_Pct_WED_Pwm_PosnSns2_DCReal_IRV, variation-point={short-label=vpWV_VeADIB_Pct_WED_Pwm_PosnSns2_DCReal_IRV, sw-syscond=1}
            WV_VeADIB_b_WED_Pwm_PosnSns1_IsPinHi1_IRV: accessed-variable=VeADIB_b_WED_Pwm_PosnSns1_IsPinHi1_IRV, variation-point={short-label=vpWV_VeADIB_b_WED_Pwm_PosnSns1_IsPinHi1_IRV, sw-syscond=1}
            WV_VeADIB_b_WED_Pwm_PosnSns1_TiOut1_IRV: accessed-variable=VeADIB_b_WED_Pwm_PosnSns1_TiOut1_IRV, variation-point={short-label=vpWV_VeADIB_b_WED_Pwm_PosnSns1_TiOut1_IRV, sw-syscond=1}
            WV_VeADIB_b_WED_Pwm_PosnSns2_IsPinHi1_IRV: accessed-variable=VeADIB_b_WED_Pwm_PosnSns2_IsPinHi1_IRV, variation-point={short-label=vpWV_VeADIB_b_WED_Pwm_PosnSns2_IsPinHi1_IRV, sw-syscond=1}
            WV_VeADIB_b_WED_Pwm_PosnSns2_TiOut1_IRV: accessed-variable=VeADIB_b_WED_Pwm_PosnSns2_TiOut1_IRV, variation-point={short-label=vpWV_VeADIB_b_WED_Pwm_PosnSns2_TiOut1_IRV, sw-syscond=1}
            WV_VeADIB_ut_WED_Pwm_PosnSns1_Prd1_IRV: accessed-variable=VeADIB_ut_WED_Pwm_PosnSns1_Prd1_IRV, variation-point={short-label=vpWV_VeADIB_ut_WED_Pwm_PosnSns1_Prd1_IRV, sw-syscond=1}
            WV_VeADIB_ut_WED_Pwm_PosnSns2_Prd1_IRV: accessed-variable=VeADIB_ut_WED_Pwm_PosnSns2_Prd1_IRV, variation-point={short-label=vpWV_VeADIB_ut_WED_Pwm_PosnSns2_Prd1_IRV, sw-syscond=1}
            WV_VeADIB_b_LtWED_FA_IRV: accessed-variable=VeADIB_b_LtWED_FA_IRV, variation-point={short-label=vpWV_VeADIB_b_LtWED_FA_IRV, sw-syscond=1}
            WV_VeADIB_b_RtWED_FA_IRV: accessed-variable=VeADIB_b_RtWED_FA_IRV, variation-point={short-label=vpWV_VeADIB_b_RtWED_FA_IRV, sw-syscond=1}
            WV_VeADIB_b_WED_Pwm_PosnSns1_FA1_IRV: accessed-variable=VeADIB_b_WED_Pwm_PosnSns1_FA1_IRV, variation-point={short-label=vpWV_VeADIB_b_WED_Pwm_PosnSns1_FA1_IRV, sw-syscond=1}
            WV_VeADIB_b_WED_Pwm_PosnSns1_FaultCriteria_IRV: accessed-variable=VeADIB_b_WED_Pwm_PosnSns1_FaultCriteria_IRV, variation-point={short-label=vpWV_VeADIB_b_WED_Pwm_PosnSns1_FaultCriteria_IRV, sw-syscond=1}
            WV_VeADIB_b_WED_Pwm_PosnSns2_FA1_IRV: accessed-variable=VeADIB_b_WED_Pwm_PosnSns2_FA1_IRV, variation-point={short-label=vpWV_VeADIB_b_WED_Pwm_PosnSns2_FA1_IRV, sw-syscond=1}
            WV_VeADIB_b_WED_Pwm_PosnSns2_FualtCriteria_IRV: accessed-variable=VeADIB_b_WED_Pwm_PosnSns2_FualtCriteria_IRV, variation-point={short-label=vpWV_VeADIB_b_WED_Pwm_PosnSns2_FualtCriteria_IRV, sw-syscond=1}
      runnable ADIB_FastTEA: variation-point={short-label=vpADIB_FastTEA, sw-syscond=1}
        data-receive-point-by-arguments:
          31 x access:
            IN_VeADAR_DC_LeftSlndPWMCmd_Value: accessed-variable=VeADAR_DC_LeftSlndPWMCmd.Value, variation-point={short-label=vpIN_VeADAR_DC_LeftSlndPWMCmd_Value, sw-syscond=1}
            IN_VeADAR_DC_RightSlndPWMCmd_Value: accessed-variable=VeADAR_DC_RightSlndPWMCmd.Value, variation-point={short-label=vpIN_VeADAR_DC_RightSlndPWMCmd_Value, sw-syscond=1}
            IN_VeADCR_U_Motor1_VsADCR_e_CnvnRes: accessed-variable=VeADCR_U_Motor1.VsADCR_e_CnvnRes, variation-point={short-label=vpIN_VeADCR_U_Motor1_VsADCR_e_CnvnRes, sw-syscond=1}
            IN_VeADCR_U_Motor2_VsADCR_e_CnvnRes: accessed-variable=VeADCR_U_Motor2.VsADCR_e_CnvnRes, variation-point={short-label=vpIN_VeADCR_U_Motor2_VsADCR_e_CnvnRes, sw-syscond=1}
            IN_VeADFB_b_A2DFault_Value: accessed-variable=VeADFB_b_A2DFault.Value, variation-point={short-label=vpIN_VeADFB_b_A2DFault_Value, sw-syscond=1}
            IN_VeDIOR_b_Hbrdg_LWEDDiagFltCircDtctd_CircOpen: accessed-variable=VeDIOR_b_Hbrdg_LWEDDiagFltCircDtctd.CircOpen, variation-point={short-label=vpIN_VeDIOR_b_Hbrdg_LWEDDiagFltCircDtctd_CircOpen, sw-syscond=1}
            IN_VeDIOR_b_Hbrdg_LWEDDiagFltCircDtctd_CircShoHi: accessed-variable=VeDIOR_b_Hbrdg_LWEDDiagFltCircDtctd.CircShoHi, variation-point={short-label=vpIN_VeDIOR_b_Hbrdg_LWEDDiagFltCircDtctd_CircShoHi, sw-syscond=1}
            IN_VeDIOR_b_Hbrdg_LWEDDiagFltCircDtctd_CircShoLo: accessed-variable=VeDIOR_b_Hbrdg_LWEDDiagFltCircDtctd.CircShoLo, variation-point={short-label=vpIN_VeDIOR_b_Hbrdg_LWEDDiagFltCircDtctd_CircShoLo, sw-syscond=1}
            IN_VeDIOR_b_Hbrdg_LWEDDiagFltCircDtctd_ShoLoad: accessed-variable=VeDIOR_b_Hbrdg_LWEDDiagFltCircDtctd.ShoLoad, variation-point={short-label=vpIN_VeDIOR_b_Hbrdg_LWEDDiagFltCircDtctd_ShoLoad, sw-syscond=1}
            IN_VeDIOR_b_Hbrdg_LWEDDiagFltOutp_DrvrOvrTempDtctd: accessed-variable=VeDIOR_b_Hbrdg_LWEDDiagFltOutp.DrvrOvrTempDtctd, variation-point={short-label=vpIN_VeDIOR_b_Hbrdg_LWEDDiagFltOutp_DrvrOvrTempDtctd, sw-syscond=1}
            IN_VeDIOR_b_Hbrdg_LWEDDiagFltOutp_DrvrOvrTempWarn: accessed-variable=VeDIOR_b_Hbrdg_LWEDDiagFltOutp.DrvrOvrTempWarn, variation-point={short-label=vpIN_VeDIOR_b_Hbrdg_LWEDDiagFltOutp_DrvrOvrTempWarn, sw-syscond=1}
            IN_VeDIOR_b_Hbrdg_LWEDDiagFltOutp_DrvrOvrVoltDtctd: accessed-variable=VeDIOR_b_Hbrdg_LWEDDiagFltOutp.DrvrOvrVoltDtctd, variation-point={short-label=vpIN_VeDIOR_b_Hbrdg_LWEDDiagFltOutp_DrvrOvrVoltDtctd, sw-syscond=1}
            IN_VeDIOR_b_Hbrdg_LWEDDiagFltOutp_DrvrUndrVoltDtctd: accessed-variable=VeDIOR_b_Hbrdg_LWEDDiagFltOutp.DrvrUndrVoltDtctd, variation-point={short-label=vpIN_VeDIOR_b_Hbrdg_LWEDDiagFltOutp_DrvrUndrVoltDtctd, sw-syscond=1}
            IN_VeDIOR_b_Hbrdg_RWEDDiagFltCircDtctd_CircOpen: accessed-variable=VeDIOR_b_Hbrdg_RWEDDiagFltCircDtctd.CircOpen, variation-point={short-label=vpIN_VeDIOR_b_Hbrdg_RWEDDiagFltCircDtctd_CircOpen, sw-syscond=1}
            IN_VeDIOR_b_Hbrdg_RWEDDiagFltCircDtctd_CircShoHi: accessed-variable=VeDIOR_b_Hbrdg_RWEDDiagFltCircDtctd.CircShoHi, variation-point={short-label=vpIN_VeDIOR_b_Hbrdg_RWEDDiagFltCircDtctd_CircShoHi, sw-syscond=1}
            IN_VeDIOR_b_Hbrdg_RWEDDiagFltCircDtctd_CircShoLo: accessed-variable=VeDIOR_b_Hbrdg_RWEDDiagFltCircDtctd.CircShoLo, variation-point={short-label=vpIN_VeDIOR_b_Hbrdg_RWEDDiagFltCircDtctd_CircShoLo, sw-syscond=1}
            IN_VeDIOR_b_Hbrdg_RWEDDiagFltCircDtctd_ShoLoad: accessed-variable=VeDIOR_b_Hbrdg_RWEDDiagFltCircDtctd.ShoLoad, variation-point={short-label=vpIN_VeDIOR_b_Hbrdg_RWEDDiagFltCircDtctd_ShoLoad, sw-syscond=1}
            IN_VeDIOR_b_Hbrdg_RWEDDiagFltOutp_DrvrOvrTempDtctd: accessed-variable=VeDIOR_b_Hbrdg_RWEDDiagFltOutp.DrvrOvrTempDtctd, variation-point={short-label=vpIN_VeDIOR_b_Hbrdg_RWEDDiagFltOutp_DrvrOvrTempDtctd, sw-syscond=1}
            IN_VeDIOR_b_Hbrdg_RWEDDiagFltOutp_DrvrOvrTempWarn: accessed-variable=VeDIOR_b_Hbrdg_RWEDDiagFltOutp.DrvrOvrTempWarn, variation-point={short-label=vpIN_VeDIOR_b_Hbrdg_RWEDDiagFltOutp_DrvrOvrTempWarn, sw-syscond=1}
            IN_VeDIOR_b_Hbrdg_RWEDDiagFltOutp_DrvrOvrVoltDtctd: accessed-variable=VeDIOR_b_Hbrdg_RWEDDiagFltOutp.DrvrOvrVoltDtctd, variation-point={short-label=vpIN_VeDIOR_b_Hbrdg_RWEDDiagFltOutp_DrvrOvrVoltDtctd, sw-syscond=1}
            IN_VeDIOR_b_Hbrdg_RWEDDiagFltOutp_DrvrUndrVoltDtctd: accessed-variable=VeDIOR_b_Hbrdg_RWEDDiagFltOutp.DrvrUndrVoltDtctd, variation-point={short-label=vpIN_VeDIOR_b_Hbrdg_RWEDDiagFltOutp_DrvrUndrVoltDtctd, sw-syscond=1}
            IN_VeDIOR_h_WheelEnd1EvADC_PWM_Inp_VeDIOR_Pct_PwmInp_DC: accessed-variable=VeDIOR_h_WheelEnd1EvADC_PWM_Inp.VeDIOR_Pct_PwmInp_DC, variation-point={short-label=vpIN_VeDIOR_h_WheelEnd1EvADC_PWM_Inp_VeDIOR_Pct_PwmInp_DC, sw-syscond=1}
            IN_VeDIOR_h_WheelEnd1EvADC_PWM_Inp_VeDIOR_b_IsPinHi: accessed-variable=VeDIOR_h_WheelEnd1EvADC_PWM_Inp.VeDIOR_b_IsPinHi, variation-point={short-label=vpIN_VeDIOR_h_WheelEnd1EvADC_PWM_Inp_VeDIOR_b_IsPinHi, sw-syscond=1}
            IN_VeDIOR_h_WheelEnd1EvADC_PWM_Inp_VeDIOR_b_PwmInp_TiOutSts: accessed-variable=VeDIOR_h_WheelEnd1EvADC_PWM_Inp.VeDIOR_b_PwmInp_TiOutSts, variation-point={short-label=vpIN_VeDIOR_h_WheelEnd1EvADC_PWM_Inp_VeDIOR_b_PwmInp_TiOutSts, sw-syscond=1}
            IN_VeDIOR_h_WheelEnd1EvADC_PWM_Inp_VeDIOR_t_PwmInp_PW: accessed-variable=VeDIOR_h_WheelEnd1EvADC_PWM_Inp.VeDIOR_t_PwmInp_PW, variation-point={short-label=vpIN_VeDIOR_h_WheelEnd1EvADC_PWM_Inp_VeDIOR_t_PwmInp_PW, sw-syscond=1}
            IN_VeDIOR_h_WheelEnd1EvADC_PWM_Inp_VeDIOR_t_PwmInp_Prd: accessed-variable=VeDIOR_h_WheelEnd1EvADC_PWM_Inp.VeDIOR_t_PwmInp_Prd, variation-point={short-label=vpIN_VeDIOR_h_WheelEnd1EvADC_PWM_Inp_VeDIOR_t_PwmInp_Prd, sw-syscond=1}
            IN_VeDIOR_h_WheelEnd2EvADC_PWM_Inp_VeDIOR_Pct_PwmInp_DC: accessed-variable=VeDIOR_h_WheelEnd2EvADC_PWM_Inp.VeDIOR_Pct_PwmInp_DC, variation-point={short-label=vpIN_VeDIOR_h_WheelEnd2EvADC_PWM_Inp_VeDIOR_Pct_PwmInp_DC, sw-syscond=1}
            IN_VeDIOR_h_WheelEnd2EvADC_PWM_Inp_VeDIOR_b_IsPinHi: accessed-variable=VeDIOR_h_WheelEnd2EvADC_PWM_Inp.VeDIOR_b_IsPinHi, variation-point={short-label=vpIN_VeDIOR_h_WheelEnd2EvADC_PWM_Inp_VeDIOR_b_IsPinHi, sw-syscond=1}
            IN_VeDIOR_h_WheelEnd2EvADC_PWM_Inp_VeDIOR_b_PwmInp_TiOutSts: accessed-variable=VeDIOR_h_WheelEnd2EvADC_PWM_Inp.VeDIOR_b_PwmInp_TiOutSts, variation-point={short-label=vpIN_VeDIOR_h_WheelEnd2EvADC_PWM_Inp_VeDIOR_b_PwmInp_TiOutSts, sw-syscond=1}
            IN_VeDIOR_h_WheelEnd2EvADC_PWM_Inp_VeDIOR_t_PwmInp_PW: accessed-variable=VeDIOR_h_WheelEnd2EvADC_PWM_Inp.VeDIOR_t_PwmInp_PW, variation-point={short-label=vpIN_VeDIOR_h_WheelEnd2EvADC_PWM_Inp_VeDIOR_t_PwmInp_PW, sw-syscond=1}
            IN_VeDIOR_h_WheelEnd2EvADC_PWM_Inp_VeDIOR_t_PwmInp_Prd: accessed-variable=VeDIOR_h_WheelEnd2EvADC_PWM_Inp.VeDIOR_t_PwmInp_Prd, variation-point={short-label=vpIN_VeDIOR_h_WheelEnd2EvADC_PWM_Inp_VeDIOR_t_PwmInp_Prd, sw-syscond=1}
        data-send-points:
          32 x access:
            OUT_VeADIB_Pct_WED_Pwm_PosnSns1_DC_Value: accessed-variable=VeADIB_Pct_WED_Pwm_PosnSns1_DC.Value, variation-point={short-label=vpOUT_VeADIB_Pct_WED_Pwm_PosnSns1_DC_Value, sw-syscond=1}
            OUT_VeADIB_b_WED_Pwm_PosnSns1_TiOut_Value: accessed-variable=VeADIB_b_WED_Pwm_PosnSns1_TiOut.Value, variation-point={short-label=vpOUT_VeADIB_b_WED_Pwm_PosnSns1_TiOut_Value, sw-syscond=1}
            OUT_VeADIB_ut_WED_Pwm_PosnSns1_Prd_Value: accessed-variable=VeADIB_ut_WED_Pwm_PosnSns1_Prd.Value, variation-point={short-label=vpOUT_VeADIB_ut_WED_Pwm_PosnSns1_Prd_Value, sw-syscond=1}
            OUT_VeADIB_ut_WED_Pwm_PosnSns1_PW_Value: accessed-variable=VeADIB_ut_WED_Pwm_PosnSns1_PW.Value, variation-point={short-label=vpOUT_VeADIB_ut_WED_Pwm_PosnSns1_PW_Value, sw-syscond=1}
            OUT_VeADIB_b_WED_Pwm_PosnSns1_IsPinHi_Value: accessed-variable=VeADIB_b_WED_Pwm_PosnSns1_IsPinHi.Value, variation-point={short-label=vpOUT_VeADIB_b_WED_Pwm_PosnSns1_IsPinHi_Value, sw-syscond=1}
            OUT_VeADIB_Pct_WEDPosnSnsRight_Value: accessed-variable=VeADIB_Pct_WEDPosnSnsRight.Value, variation-point={short-label=vpOUT_VeADIB_Pct_WEDPosnSnsRight_Value, sw-syscond=1}
            OUT_VeADIB_Pct_WED_Pwm_PosnSns2_DC_Value: accessed-variable=VeADIB_Pct_WED_Pwm_PosnSns2_DC.Value, variation-point={short-label=vpOUT_VeADIB_Pct_WED_Pwm_PosnSns2_DC_Value, sw-syscond=1}
            OUT_VeADIB_b_WED_Pwm_PosnSns2_TiOut_Value: accessed-variable=VeADIB_b_WED_Pwm_PosnSns2_TiOut.Value, variation-point={short-label=vpOUT_VeADIB_b_WED_Pwm_PosnSns2_TiOut_Value, sw-syscond=1}
            OUT_VeADIB_ut_WED_Pwm_PosnSns2_Prd_Value: accessed-variable=VeADIB_ut_WED_Pwm_PosnSns2_Prd.Value, variation-point={short-label=vpOUT_VeADIB_ut_WED_Pwm_PosnSns2_Prd_Value, sw-syscond=1}
            OUT_VeADIB_ut_WED_Pwm_PosnSns2_PW_Value: accessed-variable=VeADIB_ut_WED_Pwm_PosnSns2_PW.Value, variation-point={short-label=vpOUT_VeADIB_ut_WED_Pwm_PosnSns2_PW_Value, sw-syscond=1}
            OUT_VeADIB_b_WED_Pwm_PosnSns2_IsPinHi_Value: accessed-variable=VeADIB_b_WED_Pwm_PosnSns2_IsPinHi.Value, variation-point={short-label=vpOUT_VeADIB_b_WED_Pwm_PosnSns2_IsPinHi_Value, sw-syscond=1}
            OUT_VeADIB_Pct_WEDPosnSnsLeft_Value: accessed-variable=VeADIB_Pct_WEDPosnSnsLeft.Value, variation-point={short-label=vpOUT_VeADIB_Pct_WEDPosnSnsLeft_Value, sw-syscond=1}
            OUT_VeADIB_I_WEDLeftCurrAct_Value: accessed-variable=VeADIB_I_WEDLeftCurrAct.Value, variation-point={short-label=vpOUT_VeADIB_I_WEDLeftCurrAct_Value, sw-syscond=1}
            OUT_VeADIB_b_WEDLeftCurrActFA_Value: accessed-variable=VeADIB_b_WEDLeftCurrActFA.Value, variation-point={short-label=vpOUT_VeADIB_b_WEDLeftCurrActFA_Value, sw-syscond=1}
            OUT_VeADIB_I_WEDRightCurrAct_Value: accessed-variable=VeADIB_I_WEDRightCurrAct.Value, variation-point={short-label=vpOUT_VeADIB_I_WEDRightCurrAct_Value, sw-syscond=1}
            OUT_VeADIB_b_WEDRightCurrActFA_Value: accessed-variable=VeADIB_b_WEDRightCurrActFA.Value, variation-point={short-label=vpOUT_VeADIB_b_WEDRightCurrActFA_Value, sw-syscond=1}
            OUT_VeADIB_y_WEDLtCircLo_Value: accessed-variable=VeADIB_y_WEDLtCircLo.Value, variation-point={short-label=vpOUT_VeADIB_y_WEDLtCircLo_Value, sw-syscond=1}
            OUT_VeADIB_y_WEDLtCircHi_Value: accessed-variable=VeADIB_y_WEDLtCircHi.Value, variation-point={short-label=vpOUT_VeADIB_y_WEDLtCircHi_Value, sw-syscond=1}
            OUT_VeADIB_y_WEDLtCircOpen_Value: accessed-variable=VeADIB_y_WEDLtCircOpen.Value, variation-point={short-label=vpOUT_VeADIB_y_WEDLtCircOpen_Value, sw-syscond=1}
            OUT_VeADIB_y_WEDLtShoLoad_Value: accessed-variable=VeADIB_y_WEDLtShoLoad.Value, variation-point={short-label=vpOUT_VeADIB_y_WEDLtShoLoad_Value, sw-syscond=1}
            OUT_VeADIB_y_WEDLtDrvrOvrTempWarn_Value: accessed-variable=VeADIB_y_WEDLtDrvrOvrTempWarn.Value, variation-point={short-label=vpOUT_VeADIB_y_WEDLtDrvrOvrTempWarn_Value, sw-syscond=1}
            OUT_VeADIB_y_WEDLtDrvrOvrTemp_Value: accessed-variable=VeADIB_y_WEDLtDrvrOvrTemp.Value, variation-point={short-label=vpOUT_VeADIB_y_WEDLtDrvrOvrTemp_Value, sw-syscond=1}
            OUT_VeADIB_y_WEDLtDrvrOvrVolt_Value: accessed-variable=VeADIB_y_WEDLtDrvrOvrVolt.Value, variation-point={short-label=vpOUT_VeADIB_y_WEDLtDrvrOvrVolt_Value, sw-syscond=1}
            OUT_VeADIB_y_WEDLtDrvrUndrVolt_Value: accessed-variable=VeADIB_y_WEDLtDrvrUndrVolt.Value, variation-point={short-label=vpOUT_VeADIB_y_WEDLtDrvrUndrVolt_Value, sw-syscond=1}
            OUT_VeADIB_y_WEDRtCircLo_Value: accessed-variable=VeADIB_y_WEDRtCircLo.Value, variation-point={short-label=vpOUT_VeADIB_y_WEDRtCircLo_Value, sw-syscond=1}
            OUT_VeADIB_y_WEDRtCircHi_Value: accessed-variable=VeADIB_y_WEDRtCircHi.Value, variation-point={short-label=vpOUT_VeADIB_y_WEDRtCircHi_Value, sw-syscond=1}
            OUT_VeADIB_y_WEDRtCircOpen_Value: accessed-variable=VeADIB_y_WEDRtCircOpen.Value, variation-point={short-label=vpOUT_VeADIB_y_WEDRtCircOpen_Value, sw-syscond=1}
            OUT_VeADIB_y_WEDRtShoLoad_Value: accessed-variable=VeADIB_y_WEDRtShoLoad.Value, variation-point={short-label=vpOUT_VeADIB_y_WEDRtShoLoad_Value, sw-syscond=1}
            OUT_VeADIB_y_WEDRtDrvrOvrTempWarn_Value: accessed-variable=VeADIB_y_WEDRtDrvrOvrTempWarn.Value, variation-point={short-label=vpOUT_VeADIB_y_WEDRtDrvrOvrTempWarn_Value, sw-syscond=1}
            OUT_VeADIB_y_WEDRtDrvrOvrTemp_Value: accessed-variable=VeADIB_y_WEDRtDrvrOvrTemp.Value, variation-point={short-label=vpOUT_VeADIB_y_WEDRtDrvrOvrTemp_Value, sw-syscond=1}
            OUT_VeADIB_y_WEDRtDrvrOvrVolt_Value: accessed-variable=VeADIB_y_WEDRtDrvrOvrVolt.Value, variation-point={short-label=vpOUT_VeADIB_y_WEDRtDrvrOvrVolt_Value, sw-syscond=1}
            OUT_VeADIB_y_WEDRtDrvrUndrVolt_Value: accessed-variable=VeADIB_y_WEDRtDrvrUndrVolt.Value, variation-point={short-label=vpOUT_VeADIB_y_WEDRtDrvrUndrVolt_Value, sw-syscond=1}
        read-local-variables:
          6 x access:
            RV_VeADIB_b_LtWED_FA_IRV: accessed-variable=VeADIB_b_LtWED_FA_IRV, variation-point={short-label=vpRV_VeADIB_b_LtWED_FA_IRV, sw-syscond=1}
            RV_VeADIB_b_RtWED_FA_IRV: accessed-variable=VeADIB_b_RtWED_FA_IRV, variation-point={short-label=vpRV_VeADIB_b_RtWED_FA_IRV, sw-syscond=1}
            RV_VeADIB_b_WED_Pwm_PosnSns1_FA1_IRV: accessed-variable=VeADIB_b_WED_Pwm_PosnSns1_FA1_IRV, variation-point={short-label=vpRV_VeADIB_b_WED_Pwm_PosnSns1_FA1_IRV, sw-syscond=1}
            RV_VeADIB_b_WED_Pwm_PosnSns1_FaultCriteria_IRV: accessed-variable=VeADIB_b_WED_Pwm_PosnSns1_FaultCriteria_IRV, variation-point={short-label=vpRV_VeADIB_b_WED_Pwm_PosnSns1_FaultCriteria_IRV, sw-syscond=1}
            RV_VeADIB_b_WED_Pwm_PosnSns2_FA1_IRV: accessed-variable=VeADIB_b_WED_Pwm_PosnSns2_FA1_IRV, variation-point={short-label=vpRV_VeADIB_b_WED_Pwm_PosnSns2_FA1_IRV, sw-syscond=1}
            RV_VeADIB_b_WED_Pwm_PosnSns2_FualtCriteria_IRV: accessed-variable=VeADIB_b_WED_Pwm_PosnSns2_FualtCriteria_IRV, variation-point={short-label=vpRV_VeADIB_b_WED_Pwm_PosnSns2_FualtCriteria_IRV, sw-syscond=1}
        10 x sync call, all with timeout=1E-06:
          SC_ADIB_FastTEA_StartCheckpoint_CheckpointReached: operation=ADIB_FastTEA_StartCheckpoint.CheckpointReached, variation-point={short-label=vpSC_ADIB_FastTEA_StartCheckpoint_CheckpointReached, sw-syscond=1}
          SC_ADIB_FastTEA_StopCheckpoint_CheckpointReached: operation=ADIB_FastTEA_StopCheckpoint.CheckpointReached, variation-point={short-label=vpSC_ADIB_FastTEA_StopCheckpoint_CheckpointReached, sw-syscond=1}
          SC_ServDIOR_Hbrdg_LtWheelEndDisconnect_SetDIOR_CurrLim: operation=ServDIOR_Hbrdg_LtWheelEndDisconnect.SetDIOR_CurrLim, variation-point={short-label=vpSC_ServDIOR_Hbrdg_LtWheelEndDisconnect_SetDIOR_CurrLim, sw-syscond=1}
          SC_ServDIOR_Hbrdg_LtWheelEndDisconnect_SetDIOR_DutyCyc: operation=ServDIOR_Hbrdg_LtWheelEndDisconnect.SetDIOR_DutyCyc, variation-point={short-label=vpSC_ServDIOR_Hbrdg_LtWheelEndDisconnect_SetDIOR_DutyCyc, sw-syscond=1}
          SC_ServDIOR_Hbrdg_LtWheelEndDisconnect_SetDIOR_EnblSt: operation=ServDIOR_Hbrdg_LtWheelEndDisconnect.SetDIOR_EnblSt, variation-point={short-label=vpSC_ServDIOR_Hbrdg_LtWheelEndDisconnect_SetDIOR_EnblSt, sw-syscond=1}
          SC_ServDIOR_Hbrdg_LtWheelEndDisconnect_SetDIOR_Prd: operation=ServDIOR_Hbrdg_LtWheelEndDisconnect.SetDIOR_Prd, variation-point={short-label=vpSC_ServDIOR_Hbrdg_LtWheelEndDisconnect_SetDIOR_Prd, sw-syscond=1}
          SC_ServDIOR_Hbrdg_RtWheelEndDisconnect_SetDIOR_CurrLim: operation=ServDIOR_Hbrdg_RtWheelEndDisconnect.SetDIOR_CurrLim, variation-point={short-label=vpSC_ServDIOR_Hbrdg_RtWheelEndDisconnect_SetDIOR_CurrLim, sw-syscond=1}
          SC_ServDIOR_Hbrdg_RtWheelEndDisconnect_SetDIOR_DutyCyc: operation=ServDIOR_Hbrdg_RtWheelEndDisconnect.SetDIOR_DutyCyc, variation-point={short-label=vpSC_ServDIOR_Hbrdg_RtWheelEndDisconnect_SetDIOR_DutyCyc, sw-syscond=1}
          SC_ServDIOR_Hbrdg_RtWheelEndDisconnect_SetDIOR_EnblSt: operation=ServDIOR_Hbrdg_RtWheelEndDisconnect.SetDIOR_EnblSt, variation-point={short-label=vpSC_ServDIOR_Hbrdg_RtWheelEndDisconnect_SetDIOR_EnblSt, sw-syscond=1}
          SC_ServDIOR_Hbrdg_RtWheelEndDisconnect_SetDIOR_Prd: operation=ServDIOR_Hbrdg_RtWheelEndDisconnect.SetDIOR_Prd, variation-point={short-label=vpSC_ServDIOR_Hbrdg_RtWheelEndDisconnect_SetDIOR_Prd, sw-syscond=1}
        written-local-variables:
          8 x access:
            WV_VeADIB_Pct_WED_Pwm_PosnSns1_DCReal_IRV: accessed-variable=VeADIB_Pct_WED_Pwm_PosnSns1_DCReal_IRV, variation-point={short-label=vpWV_VeADIB_Pct_WED_Pwm_PosnSns1_DCReal_IRV, sw-syscond=1}
            WV_VeADIB_Pct_WED_Pwm_PosnSns2_DCReal_IRV: accessed-variable=VeADIB_Pct_WED_Pwm_PosnSns2_DCReal_IRV, variation-point={short-label=vpWV_VeADIB_Pct_WED_Pwm_PosnSns2_DCReal_IRV, sw-syscond=1}
            WV_VeADIB_b_WED_Pwm_PosnSns1_IsPinHi1_IRV: accessed-variable=VeADIB_b_WED_Pwm_PosnSns1_IsPinHi1_IRV, variation-point={short-label=vpWV_VeADIB_b_WED_Pwm_PosnSns1_IsPinHi1_IRV, sw-syscond=1}
            WV_VeADIB_b_WED_Pwm_PosnSns1_TiOut1_IRV: accessed-variable=VeADIB_b_WED_Pwm_PosnSns1_TiOut1_IRV, variation-point={short-label=vpWV_VeADIB_b_WED_Pwm_PosnSns1_TiOut1_IRV, sw-syscond=1}
            WV_VeADIB_b_WED_Pwm_PosnSns2_IsPinHi1_IRV: accessed-variable=VeADIB_b_WED_Pwm_PosnSns2_IsPinHi1_IRV, variation-point={short-label=vpWV_VeADIB_b_WED_Pwm_PosnSns2_IsPinHi1_IRV, sw-syscond=1}
            WV_VeADIB_b_WED_Pwm_PosnSns2_TiOut1_IRV: accessed-variable=VeADIB_b_WED_Pwm_PosnSns2_TiOut1_IRV, variation-point={short-label=vpWV_VeADIB_b_WED_Pwm_PosnSns2_TiOut1_IRV, sw-syscond=1}
            WV_VeADIB_ut_WED_Pwm_PosnSns1_Prd1_IRV: accessed-variable=VeADIB_ut_WED_Pwm_PosnSns1_Prd1_IRV, variation-point={short-label=vpWV_VeADIB_ut_WED_Pwm_PosnSns1_Prd1_IRV, sw-syscond=1}
            WV_VeADIB_ut_WED_Pwm_PosnSns2_Prd1_IRV: accessed-variable=VeADIB_ut_WED_Pwm_PosnSns2_Prd1_IRV, variation-point={short-label=vpWV_VeADIB_ut_WED_Pwm_PosnSns2_Prd1_IRV, sw-syscond=1}
      runnable ADIB_MedTEB
        data-receive-point-by-arguments:
          23 x access:
            IN_VeDFIR_b_DsblDiagFailSafe_Value: accessed-variable=VeDFIR_b_DsblDiagFailSafe.Value, variation-point={short-label=vpIN_VeDFIR_b_DsblDiagFailSafe_Value, sw-syscond=1}
            IN_VeDFIR_b_IsDiagGlobalConditionsValid_Value: accessed-variable=VeDFIR_b_IsDiagGlobalConditionsValid.Value, variation-point={short-label=vpIN_VeDFIR_b_IsDiagGlobalConditionsValid_Value, sw-syscond=1}
            IN_VeDFIR_b_PostCodeClrDiagDsbl_Value: accessed-variable=VeDFIR_b_PostCodeClrDiagDsbl.Value, variation-point={short-label=vpIN_VeDFIR_b_PostCodeClrDiagDsbl_Value, sw-syscond=1}
            IN_VeDIOR_b_Hbrdg_LtWheelEndDisconnectDiagCmn_b_FailrPrsnt: accessed-variable=VeDIOR_b_Hbrdg_LtWheelEndDisconnectDiagCmn.b_FailrPrsnt, variation-point={short-label=vpIN_VeDIOR_b_Hbrdg_LtWheelEndDisconnectDiagCmn_b_FailrPrsnt, sw-syscond=1}
            IN_VeDIOR_b_Hbrdg_RtWheelEndDisconnectDiagCmn_b_FailrPrsnt: accessed-variable=VeDIOR_b_Hbrdg_RtWheelEndDisconnectDiagCmn.b_FailrPrsnt, variation-point={short-label=vpIN_VeDIOR_b_Hbrdg_RtWheelEndDisconnectDiagCmn_b_FailrPrsnt, sw-syscond=1}
            IN_VeDMAB_y_StatusByte_LF_WHL_HubDisConActCntrl_Value: accessed-variable=VeDMAB_y_StatusByte_LF_WHL_HubDisConActCntrl.Value, variation-point={short-label=vpIN_VeDMAB_y_StatusByte_LF_WHL_HubDisConActCntrl_Value, sw-syscond=1}
            IN_VeDMAB_y_StatusByte_LF_WHL_HubDisConActPosSnsr_Value: accessed-variable=VeDMAB_y_StatusByte_LF_WHL_HubDisConActPosSnsr.Value, variation-point={short-label=vpIN_VeDMAB_y_StatusByte_LF_WHL_HubDisConActPosSnsr_Value, sw-syscond=1}
            IN_VeDMAB_y_StatusByte_LF_WHL_HubDisConActPosSnsrCktPerf_Value: accessed-variable=VeDMAB_y_StatusByte_LF_WHL_HubDisConActPosSnsrCktPerf.Value, variation-point={short-label=vpIN_VeDMAB_y_StatusByte_LF_WHL_HubDisConActPosSnsrCktPerf_Value, sw-syscond=1}
            IN_VeDMAB_y_StatusByte_RF_WHL_HubDisConActCntrl_Value: accessed-variable=VeDMAB_y_StatusByte_RF_WHL_HubDisConActCntrl.Value, variation-point={short-label=vpIN_VeDMAB_y_StatusByte_RF_WHL_HubDisConActCntrl_Value, sw-syscond=1}
            IN_VeDMAB_y_StatusByte_RF_WHL_HubDisConActPosSnsr_Value: accessed-variable=VeDMAB_y_StatusByte_RF_WHL_HubDisConActPosSnsr.Value, variation-point={short-label=vpIN_VeDMAB_y_StatusByte_RF_WHL_HubDisConActPosSnsr_Value, sw-syscond=1}
            IN_VeDMAB_y_StatusByte_RF_WHL_HubDisConActPosSnsrCktPerf_Value: accessed-variable=VeDMAB_y_StatusByte_RF_WHL_HubDisConActPosSnsrCktPerf.Value, variation-point={short-label=vpIN_VeDMAB_y_StatusByte_RF_WHL_HubDisConActPosSnsrCktPerf_Value, sw-syscond=1}
            IN_VeDMAB_y_StatusByte_SnsrRefVolt5CktHi_Value: accessed-variable=VeDMAB_y_StatusByte_SnsrRefVolt5CktHi.Value, variation-point={short-label=vpIN_VeDMAB_y_StatusByte_SnsrRefVolt5CktHi_Value, sw-syscond=1}
            IN_VeDMAB_y_StatusByte_SnsrRefVolt5CktLo_Value: accessed-variable=VeDMAB_y_StatusByte_SnsrRefVolt5CktLo.Value, variation-point={short-label=vpIN_VeDMAB_y_StatusByte_SnsrRefVolt5CktLo_Value, sw-syscond=1}
            IN_VeDMAB_y_StatusByte_SnsrRefVolt6CktHi_Value: accessed-variable=VeDMAB_y_StatusByte_SnsrRefVolt6CktHi.Value, variation-point={short-label=vpIN_VeDMAB_y_StatusByte_SnsrRefVolt6CktHi_Value, sw-syscond=1}
            IN_VeDMAB_y_StatusByte_SnsrRefVolt6CktLo_Value: accessed-variable=VeDMAB_y_StatusByte_SnsrRefVolt6CktLo.Value, variation-point={short-label=vpIN_VeDMAB_y_StatusByte_SnsrRefVolt6CktLo_Value, sw-syscond=1}
            IN_VeDMAB_y_StatusByte_SysVoltHi_Value: accessed-variable=VeDMAB_y_StatusByte_SysVoltHi.Value, variation-point={short-label=vpIN_VeDMAB_y_StatusByte_SysVoltHi_Value, sw-syscond=1}
            IN_VeDMAB_y_StatusByte_SysVoltLo_Value: accessed-variable=VeDMAB_y_StatusByte_SysVoltLo.Value, variation-point={short-label=vpIN_VeDMAB_y_StatusByte_SysVoltLo_Value, sw-syscond=1}
            IN_VeNVMB_Cnt_LtWEDElecFlt_MFOP_Value: accessed-variable=VeNVMB_Cnt_LtWEDElecFlt_MFOP.Value, variation-point={short-label=vpIN_VeNVMB_Cnt_LtWEDElecFlt_MFOP_Value, sw-syscond=1}
            IN_VeNVMB_Cnt_RtWEDElecFlt_MFOP_Value: accessed-variable=VeNVMB_Cnt_RtWEDElecFlt_MFOP.Value, variation-point={short-label=vpIN_VeNVMB_Cnt_RtWEDElecFlt_MFOP_Value, sw-syscond=1}
            IN_VeNVMB_Cnt_WEDPosnSnsr1ElecFlt_MFOP_Value: accessed-variable=VeNVMB_Cnt_WEDPosnSnsr1ElecFlt_MFOP.Value, variation-point={short-label=vpIN_VeNVMB_Cnt_WEDPosnSnsr1ElecFlt_MFOP_Value, sw-syscond=1}
            IN_VeNVMB_Cnt_WEDPosnSnsr1PosnOOR_MFOP_Value: accessed-variable=VeNVMB_Cnt_WEDPosnSnsr1PosnOOR_MFOP.Value, variation-point={short-label=vpIN_VeNVMB_Cnt_WEDPosnSnsr1PosnOOR_MFOP_Value, sw-syscond=1}
            IN_VeNVMB_Cnt_WEDPosnSnsr2ElecFlt_MFOP_Value: accessed-variable=VeNVMB_Cnt_WEDPosnSnsr2ElecFlt_MFOP.Value, variation-point={short-label=vpIN_VeNVMB_Cnt_WEDPosnSnsr2ElecFlt_MFOP_Value, sw-syscond=1}
            IN_VeNVMB_Cnt_WEDPosnSnsr2PosnOOR_MFOP_Value: accessed-variable=VeNVMB_Cnt_WEDPosnSnsr2PosnOOR_MFOP.Value, variation-point={short-label=vpIN_VeNVMB_Cnt_WEDPosnSnsr2PosnOOR_MFOP_Value, sw-syscond=1}
        data-send-points:
          14 x access:
            OUT_VeADIB_b_WED_Pwm_PosnSns1_FA_Value: accessed-variable=VeADIB_b_WED_Pwm_PosnSns1_FA.Value, variation-point={short-label=vpOUT_VeADIB_b_WED_Pwm_PosnSns1_FA_Value, sw-syscond=1}
            OUT_VeADIB_e_FaultSts_RF_WHL_HubDisConActPosSnsrCktPerf_Value: accessed-variable=VeADIB_e_FaultSts_RF_WHL_HubDisConActPosSnsrCktPerf.Value, variation-point={short-label=vpOUT_VeADIB_e_FaultSts_RF_WHL_HubDisConActPosSnsrCktPerf_Value, sw-syscond=1}
            OUT_VeADIB_e_FaultSts_RF_WHL_HubDisConActPosSnsr_Value: accessed-variable=VeADIB_e_FaultSts_RF_WHL_HubDisConActPosSnsr.Value, variation-point={short-label=vpOUT_VeADIB_e_FaultSts_RF_WHL_HubDisConActPosSnsr_Value, sw-syscond=1}
            OUT_VeADIB_Cnt_WEDPosnSnsr1ElecFlt_MFOP_Value: accessed-variable=VeADIB_Cnt_WEDPosnSnsr1ElecFlt_MFOP.Value, variation-point={short-label=vpOUT_VeADIB_Cnt_WEDPosnSnsr1ElecFlt_MFOP_Value, sw-syscond=1}
            OUT_VeADIB_Cnt_WEDPosnSnsr1PosnOOR_MFOP_Value: accessed-variable=VeADIB_Cnt_WEDPosnSnsr1PosnOOR_MFOP.Value, variation-point={short-label=vpOUT_VeADIB_Cnt_WEDPosnSnsr1PosnOOR_MFOP_Value, sw-syscond=1}
            OUT_VeADIB_b_WED_Pwm_PosnSns2_FA_Value: accessed-variable=VeADIB_b_WED_Pwm_PosnSns2_FA.Value, variation-point={short-label=vpOUT_VeADIB_b_WED_Pwm_PosnSns2_FA_Value, sw-syscond=1}
            OUT_VeADIB_e_FaultSts_LF_WHL_HubDisConActPosSnsr_Value: accessed-variable=VeADIB_e_FaultSts_LF_WHL_HubDisConActPosSnsr.Value, variation-point={short-label=vpOUT_VeADIB_e_FaultSts_LF_WHL_HubDisConActPosSnsr_Value, sw-syscond=1}
            OUT_VeADIB_e_FaultSts_LF_WHL_HubDisConActPosSnsrCktPerf_Value: accessed-variable=VeADIB_e_FaultSts_LF_WHL_HubDisConActPosSnsrCktPerf.Value, variation-point={short-label=vpOUT_VeADIB_e_FaultSts_LF_WHL_HubDisConActPosSnsrCktPerf_Value, sw-syscond=1}
            OUT_VeADIB_Cnt_WEDPosnSnsr2ElecFlt_MFOP_Value: accessed-variable=VeADIB_Cnt_WEDPosnSnsr2ElecFlt_MFOP.Value, variation-point={short-label=vpOUT_VeADIB_Cnt_WEDPosnSnsr2ElecFlt_MFOP_Value, sw-syscond=1}
            OUT_VeADIB_Cnt_WEDPosnSnsr2PosnOOR_MFOP_Value: accessed-variable=VeADIB_Cnt_WEDPosnSnsr2PosnOOR_MFOP.Value, variation-point={short-label=vpOUT_VeADIB_Cnt_WEDPosnSnsr2PosnOOR_MFOP_Value, sw-syscond=1}
            OUT_VeADIB_e_FaultSts_LF_WHL_HubDisConActCntrl_Value: accessed-variable=VeADIB_e_FaultSts_LF_WHL_HubDisConActCntrl.Value, variation-point={short-label=vpOUT_VeADIB_e_FaultSts_LF_WHL_HubDisConActCntrl_Value, sw-syscond=1}
            OUT_VeADIB_e_FaultSts_RF_WHL_HubDisConActCntrl_Value: accessed-variable=VeADIB_e_FaultSts_RF_WHL_HubDisConActCntrl.Value, variation-point={short-label=vpOUT_VeADIB_e_FaultSts_RF_WHL_HubDisConActCntrl_Value, sw-syscond=1}
            OUT_VeADIB_Cnt_RtWEDElecFlt_MFOP_Value: accessed-variable=VeADIB_Cnt_RtWEDElecFlt_MFOP.Value, variation-point={short-label=vpOUT_VeADIB_Cnt_RtWEDElecFlt_MFOP_Value, sw-syscond=1}
            OUT_VeADIB_Cnt_LtWEDElecFlt_MFOP_Value: accessed-variable=VeADIB_Cnt_LtWEDElecFlt_MFOP.Value, variation-point={short-label=vpOUT_VeADIB_Cnt_LtWEDElecFlt_MFOP_Value, sw-syscond=1}
        read-local-variables:
          8 x access:
            RV_VeADIB_Pct_WED_Pwm_PosnSns1_DCReal_IRV: accessed-variable=VeADIB_Pct_WED_Pwm_PosnSns1_DCReal_IRV, variation-point={short-label=vpRV_VeADIB_Pct_WED_Pwm_PosnSns1_DCReal_IRV, sw-syscond=1}
            RV_VeADIB_Pct_WED_Pwm_PosnSns2_DCReal_IRV: accessed-variable=VeADIB_Pct_WED_Pwm_PosnSns2_DCReal_IRV, variation-point={short-label=vpRV_VeADIB_Pct_WED_Pwm_PosnSns2_DCReal_IRV, sw-syscond=1}
            RV_VeADIB_b_WED_Pwm_PosnSns1_IsPinHi1_IRV: accessed-variable=VeADIB_b_WED_Pwm_PosnSns1_IsPinHi1_IRV, variation-point={short-label=vpRV_VeADIB_b_WED_Pwm_PosnSns1_IsPinHi1_IRV, sw-syscond=1}
            RV_VeADIB_b_WED_Pwm_PosnSns1_TiOut1_IRV: accessed-variable=VeADIB_b_WED_Pwm_PosnSns1_TiOut1_IRV, variation-point={short-label=vpRV_VeADIB_b_WED_Pwm_PosnSns1_TiOut1_IRV, sw-syscond=1}
            RV_VeADIB_b_WED_Pwm_PosnSns2_IsPinHi1_IRV: accessed-variable=VeADIB_b_WED_Pwm_PosnSns2_IsPinHi1_IRV, variation-point={short-label=vpRV_VeADIB_b_WED_Pwm_PosnSns2_IsPinHi1_IRV, sw-syscond=1}
            RV_VeADIB_b_WED_Pwm_PosnSns2_TiOut1_IRV: accessed-variable=VeADIB_b_WED_Pwm_PosnSns2_TiOut1_IRV, variation-point={short-label=vpRV_VeADIB_b_WED_Pwm_PosnSns2_TiOut1_IRV, sw-syscond=1}
            RV_VeADIB_ut_WED_Pwm_PosnSns1_Prd1_IRV: accessed-variable=VeADIB_ut_WED_Pwm_PosnSns1_Prd1_IRV, variation-point={short-label=vpRV_VeADIB_ut_WED_Pwm_PosnSns1_Prd1_IRV, sw-syscond=1}
            RV_VeADIB_ut_WED_Pwm_PosnSns2_Prd1_IRV: accessed-variable=VeADIB_ut_WED_Pwm_PosnSns2_Prd1_IRV, variation-point={short-label=vpRV_VeADIB_ut_WED_Pwm_PosnSns2_Prd1_IRV, sw-syscond=1}
        sync call SC_ADIB_MedTEB_StartCheckpoint_CheckpointReached: operation=ADIB_MedTEB_StartCheckpoint.CheckpointReached, timeout=1E-06
        sync call SC_ADIB_MedTEB_StopCheckpoint_CheckpointReached: operation=ADIB_MedTEB_StopCheckpoint.CheckpointReached, timeout=1E-06
        written-local-variables:
          6 x access:
            WV_VeADIB_b_LtWED_FA_IRV: accessed-variable=VeADIB_b_LtWED_FA_IRV, variation-point={short-label=vpWV_VeADIB_b_LtWED_FA_IRV, sw-syscond=1}
            WV_VeADIB_b_RtWED_FA_IRV: accessed-variable=VeADIB_b_RtWED_FA_IRV, variation-point={short-label=vpWV_VeADIB_b_RtWED_FA_IRV, sw-syscond=1}
            WV_VeADIB_b_WED_Pwm_PosnSns1_FA1_IRV: accessed-variable=VeADIB_b_WED_Pwm_PosnSns1_FA1_IRV, variation-point={short-label=vpWV_VeADIB_b_WED_Pwm_PosnSns1_FA1_IRV, sw-syscond=1}
            WV_VeADIB_b_WED_Pwm_PosnSns1_FaultCriteria_IRV: accessed-variable=VeADIB_b_WED_Pwm_PosnSns1_FaultCriteria_IRV, variation-point={short-label=vpWV_VeADIB_b_WED_Pwm_PosnSns1_FaultCriteria_IRV, sw-syscond=1}
            WV_VeADIB_b_WED_Pwm_PosnSns2_FA1_IRV: accessed-variable=VeADIB_b_WED_Pwm_PosnSns2_FA1_IRV, variation-point={short-label=vpWV_VeADIB_b_WED_Pwm_PosnSns2_FA1_IRV, sw-syscond=1}
            WV_VeADIB_b_WED_Pwm_PosnSns2_FualtCriteria_IRV: accessed-variable=VeADIB_b_WED_Pwm_PosnSns2_FualtCriteria_IRV, variation-point={short-label=vpWV_VeADIB_b_WED_Pwm_PosnSns2_FualtCriteria_IRV, sw-syscond=1}
      variation point proxy Variant_ADIB_WED_Presence: category=CONDITION, condition-access=1
